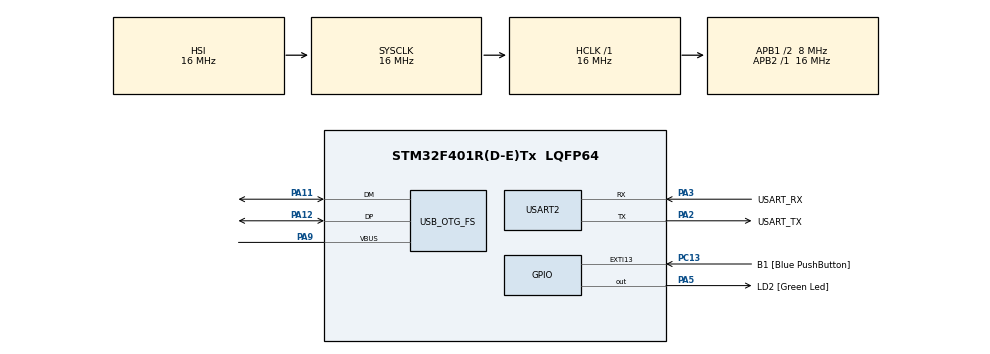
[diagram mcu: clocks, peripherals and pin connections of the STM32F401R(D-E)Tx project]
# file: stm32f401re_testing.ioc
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Mcu.Family=STM32F4
Mcu.Name=STM32F401R(D-E)Tx
Mcu.Package=LQFP64
NVIC.OTG_FS_IRQn=true\:0\:0\:false\:false\:true\:false\:true
NVIC.PriorityGroup=NVIC_PRIORITYGROUP_0
NVIC.USART2_IRQn=true\:0\:0\:false\:false\:true\:true\:true
PA11.Mode=Device_Only
PA11.Signal=USB_OTG_FS_DM
PA12.Mode=Device_Only
PA12.Signal=USB_OTG_FS_DP
PA13.GPIO_Label=TMS
PA13.Mode=Serial_Wire
PA13.Signal=SYS_JTMS-SWDIO
PA14.GPIO_Label=TCK
PA14.Mode=Serial_Wire
PA14.Signal=SYS_JTCK-SWCLK
PA2.GPIO_Label=USART_TX
PA2.GPIO_Mode=GPIO_MODE_AF_PP
PA2.GPIO_PuPd=GPIO_NOPULL
PA2.GPIO_Speed=GPIO_SPEED_FREQ_LOW
PA2.Mode=Asynchronous
PA2.Signal=USART2_TX
PA3.GPIO_Label=USART_RX
PA3.GPIO_Mode=GPIO_MODE_AF_PP
PA3.GPIO_PuPd=GPIO_NOPULL
PA3.GPIO_Speed=GPIO_SPEED_FREQ_LOW
PA3.Mode=Asynchronous
PA3.Signal=USART2_RX
PA5.GPIO_Label=LD2 [Green Led]
PA5.GPIO_Mode=GPIO_MODE_OUTPUT_PP
PA5.GPIO_PuPd=GPIO_NOPULL
PA5.GPIO_Speed=GPIO_SPEED_FREQ_LOW
PA5.Signal=GPIO_Output
PA9.Mode=Activate_VBUS
PA9.Signal=USB_OTG_FS_VBUS
PB3.GPIO_Label=SWO
PB3.Signal=SYS_JTDO-SWO
PC13-ANTI_TAMP.GPIO_Label=B1 [Blue PushButton]
PC13-ANTI_TAMP.GPIO_ModeDefaultEXTI=GPIO_MODE_IT_FALLING
PC13-ANTI_TAMP.GPIO_PuPd=GPIO_NOPULL
PC13-ANTI_TAMP.Signal=GPXTI13
PC14-OSC32_IN.Mode=LSE-External-Oscillator
PC14-OSC32_IN.Signal=RCC_OSC32_IN
PC15-OSC32_OUT.Mode=LSE-External-Oscillator
PC15-OSC32_OUT.Signal=RCC_OSC32_OUT
PH0\ -\ OSC_IN.Mode=HSE-External-Clock-Source
PH0\ -\ OSC_IN.Signal=RCC_OSC_IN
PH1\ -\ OSC_OUT.Mode=HSE-External-Clock-Source
PH1\ -\ OSC_OUT.Signal=RCC_OSC_OUT
ProjectManager.HeapSize=0x200
ProjectManager.StackSize=0x400
ProjectManager.TargetToolchain=STM32CubeIDE
RCC.48MHZClocksFreq_Value=48000000
RCC.AHBFreq_Value=16000000
RCC.APB1CLKDivider=RCC_HCLK_DIV2
RCC.APB1Freq_Value=8000000
RCC.APB1TimFreq_Value=16000000
RCC.APB2Freq_Value=16000000
RCC.APB2TimFreq_Value=16000000
RCC.CortexFreq_Value=16000000
RCC.HCLKFreq_Value=16000000
RCC.HSE_VALUE=8000000
RCC.HSI_VALUE=16000000
RCC.PLLM=4
RCC.PLLN=72
RCC.PLLP=RCC_PLLP_DIV4
RCC.PLLQ=3
RCC.SYSCLKFreq_VALUE=16000000
RCC.VCOOutputFreq_Value=144000000
USART2.VirtualMode=VM_ASYNC
USB_DEVICE.CLASS_NAME_FS=CDC
USB_DEVICE.VirtualMode-CDC_FS=Cdc
USB_DEVICE.VirtualModeFS=Cdc_FS
USB_OTG_FS.VirtualMode=Device_Only
VP_USB_DEVICE_VS_USB_DEVICE_CDC_FS.Mode=CDC_FS
board=NUCLEO-F401RE

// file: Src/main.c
/* USER CODE BEGIN Header */
/**
  ******************************************************************************
  * @file           : main.c
  * @brief          : Main program body
  ******************************************************************************
  * @attention
  *
  * <h2><center>&copy; Copyright (c) 2019 STMicroelectronics.
  * All rights reserved.</center></h2>
  *
  * This software component is licensed by ST under BSD 3-Clause license,
  * the "License"; You may not use this file except in compliance with the
  * License. You may obtain a copy of the License at:
  *                        opensource.org/licenses/BSD-3-Clause
  *
  ******************************************************************************
  */
/* USER CODE END Header */

#include "main.h"
#include "usb_device.h"
#include "stm32f4xx_hal_gpio.h"
#include "usb_device.h"
#include "usbd_cdc_if.h"

/* USER CODE BEGIN PD */
#define STATE_OP1 0
#define STATE_OP2 1
#define STATE_RESULT 2

#define ADD '+'
#define SUBTRACT '-'
#define MULTIPLY '*'
#define DIVIDE '/'
/* USER CODE END PD */

UART_HandleTypeDef huart2;

/* USER CODE BEGIN PV */
uint8_t key_buffer[100]; // Define a buffer for holding incoming key presses
int key_receive_index = 0;
int key_processing_index = 0;
/* USER CODE END PV */

void SystemClock_Config(void);
static void MX_GPIO_Init(void);
static void MX_USART2_UART_Init(void);

/* USER CODE BEGIN PFP */
int is_key_number(uint8_t key);
/* USER CODE END PFP */

int main(void)
{

  /* MCU Configuration--------------------------------------------------------*/

  /* Reset of all peripherals, Initializes the Flash interface and the Systick. */
  HAL_Init();

  /* Configure the system clock */
  SystemClock_Config();

  /* Initialize all configured peripherals */
  MX_GPIO_Init();
  MX_USART2_UART_Init();
  MX_USB_DEVICE_Init();

  /* USER CODE BEGIN 2 */
  int state = STATE_OP1;
  int op1 = 0, op2 = 0, result = 0;
  char operation = ADD;
  /* USER CODE END 2 */

  /* Infinite loop */
  while (1)
  {

	  // Reads characters from receive buffer and processes them
	  uint8_t key = key_buffer[key_processing_index];

	  // Only process characters if it isn't NULL
	  if (key != '\0')
	  {
		  // Reset spot in buffer to NULL and increment index
		  key_buffer[key_processing_index] = '\0';
		  key_processing_index = (key_processing_index >= (100 - 1)) ? 0 : key_processing_index + 1;

		  // Handle calculator input differently based on state
		  if (state == STATE_OP1)
		  {
			  // Add newest number to operand and print to terminal
			  if (is_key_number(key))
			  {
				  op1 = (op1 * 10) + (key - '0');
				  CDC_Transmit_FS(&key, 1);
			  }

			  // Set operation and change to entering second operand
			  else if ((key == ADD) || (key == SUBTRACT) || (key == MULTIPLY) || (key == DIVIDE))
			  {
				  operation = key;
				  CDC_Transmit_FS(&key, 1);
				  state = STATE_OP2;
			  }
		  }

		  else if (state == STATE_OP2)
		  {
			  // Add newest number to operand and print to terminal
			  if (is_key_number(key))
			  {
				  op2 = (op2 * 10) + (key - '0');
				  CDC_Transmit_FS(&key, 1);
			  }

			  // Pressing equals computes the result and prints it to the screen
			  else if (key == '=')
			  {
				  // Compute the result
				  if (operation == ADD)
				  {
					  result = op1 + op2;
				  }
				  else if (operation == SUBTRACT)
				  {
					  result = op1 - op2;
				  }
				  else if (operation == MULTIPLY)
				  {
					  result = op1 * op2;
				  }
				  else if (operation == DIVIDE)
				  {
					  result = op1 / op2;
				  }

				  // Define a buffer for the result and use sprintf() to format it
				  uint8_t result_print_buffer[100];
				  sprintf(result_print_buffer, "\r\n=%d\r\n", result);

				  // Determine the length of the buffer by counting to the first NULL character
				  uint32_t length = 0;
				  while (result_print_buffer[length] != '\0')
				  {
					  length++;
				  }

				  // If the result length is not 0, print the result
				  if (length > 0)
				  {
					  CDC_Transmit_FS(result_print_buffer, length);
				  }
				  else
				  {
					  CDC_Transmit_FS("\r\nERROR\r\n", sizeof("\r\nERROR\r\n"));
				  }

				  // Reset the operands and result, and then reset back to the first state
				  op1 = 0;
				  op2 = 0;
				  result = 0;
				  operation = ADD;
				  state = STATE_OP1;
			  }
		  }
	  }

  }
}

void SystemClock_Config(void)
{
  RCC_OscInitTypeDef RCC_OscInitStruct = {0};
  RCC_ClkInitTypeDef RCC_ClkInitStruct = {0};

  /** Configure the main internal regulator output voltage
  */
  __HAL_RCC_PWR_CLK_ENABLE();
  __HAL_PWR_VOLTAGESCALING_CONFIG(PWR_REGULATOR_VOLTAGE_SCALE2);
  /** Initializes the CPU, AHB and APB busses clocks
  */
  RCC_OscInitStruct.OscillatorType = RCC_OSCILLATORTYPE_HSI|RCC_OSCILLATORTYPE_HSE;
  RCC_OscInitStruct.HSEState = RCC_HSE_BYPASS;
  RCC_OscInitStruct.HSIState = RCC_HSI_ON;
  RCC_OscInitStruct.HSICalibrationValue = RCC_HSICALIBRATION_DEFAULT;
  RCC_OscInitStruct.PLL.PLLState = RCC_PLL_ON;
  RCC_OscInitStruct.PLL.PLLSource = RCC_PLLSOURCE_HSE;
  RCC_OscInitStruct.PLL.PLLM = 4;
  RCC_OscInitStruct.PLL.PLLN = 72;
  RCC_OscInitStruct.PLL.PLLP = RCC_PLLP_DIV4;
  RCC_OscInitStruct.PLL.PLLQ = 3;
  if (HAL_RCC_OscConfig(&RCC_OscInitStruct) != HAL_OK)
  {
    Error_Handler();
  }
  /** Initializes the CPU, AHB and APB busses clocks
  */
  RCC_ClkInitStruct.ClockType = RCC_CLOCKTYPE_HCLK|RCC_CLOCKTYPE_SYSCLK
                              |RCC_CLOCKTYPE_PCLK1|RCC_CLOCKTYPE_PCLK2;
  RCC_ClkInitStruct.SYSCLKSource = RCC_SYSCLKSOURCE_HSI;
  RCC_ClkInitStruct.AHBCLKDivider = RCC_SYSCLK_DIV1;
  RCC_ClkInitStruct.APB1CLKDivider = RCC_HCLK_DIV2;
  RCC_ClkInitStruct.APB2CLKDivider = RCC_HCLK_DIV1;

  if (HAL_RCC_ClockConfig(&RCC_ClkInitStruct, FLASH_LATENCY_0) != HAL_OK)
  {
    Error_Handler();
  }
}

static void MX_USART2_UART_Init(void)
{

  huart2.Instance = USART2;
  huart2.Init.BaudRate = 115200;
  huart2.Init.WordLength = UART_WORDLENGTH_8B;
  huart2.Init.StopBits = UART_STOPBITS_1;
  huart2.Init.Parity = UART_PARITY_NONE;
  huart2.Init.Mode = UART_MODE_TX_RX;
  huart2.Init.HwFlowCtl = UART_HWCONTROL_NONE;
  huart2.Init.OverSampling = UART_OVERSAMPLING_16;
  if (HAL_UART_Init(&huart2) != HAL_OK)
  {
    Error_Handler();
  }

}

static void MX_GPIO_Init(void)
{
  GPIO_InitTypeDef GPIO_InitStruct = {0};

  /* GPIO Ports Clock Enable */
  __HAL_RCC_GPIOC_CLK_ENABLE();
  __HAL_RCC_GPIOH_CLK_ENABLE();
  __HAL_RCC_GPIOA_CLK_ENABLE();
  __HAL_RCC_GPIOB_CLK_ENABLE();

  /*Configure GPIO pin Output Level */
  HAL_GPIO_WritePin(LD2_GPIO_Port, LD2_Pin, GPIO_PIN_RESET);

  /*Configure GPIO pin : B1_Pin */
  GPIO_InitStruct.Pin = B1_Pin;
  GPIO_InitStruct.Mode = GPIO_MODE_IT_FALLING;
  GPIO_InitStruct.Pull = GPIO_NOPULL;
  HAL_GPIO_Init(B1_GPIO_Port, &GPIO_InitStruct);

  /*Configure GPIO pin : LD2_Pin */
  GPIO_InitStruct.Pin = LD2_Pin;
  GPIO_InitStruct.Mode = GPIO_MODE_OUTPUT_PP;
  GPIO_InitStruct.Pull = GPIO_NOPULL;
  GPIO_InitStruct.Speed = GPIO_SPEED_FREQ_LOW;
  HAL_GPIO_Init(LD2_GPIO_Port, &GPIO_InitStruct);

}

void Error_Handler(void)
{
}

/************************ (C) COPYRIGHT STMicroelectronics *****END OF FILE****/

int is_key_number(uint8_t key)
{
	return ((key >= '0') && (key <= '9'));
}
